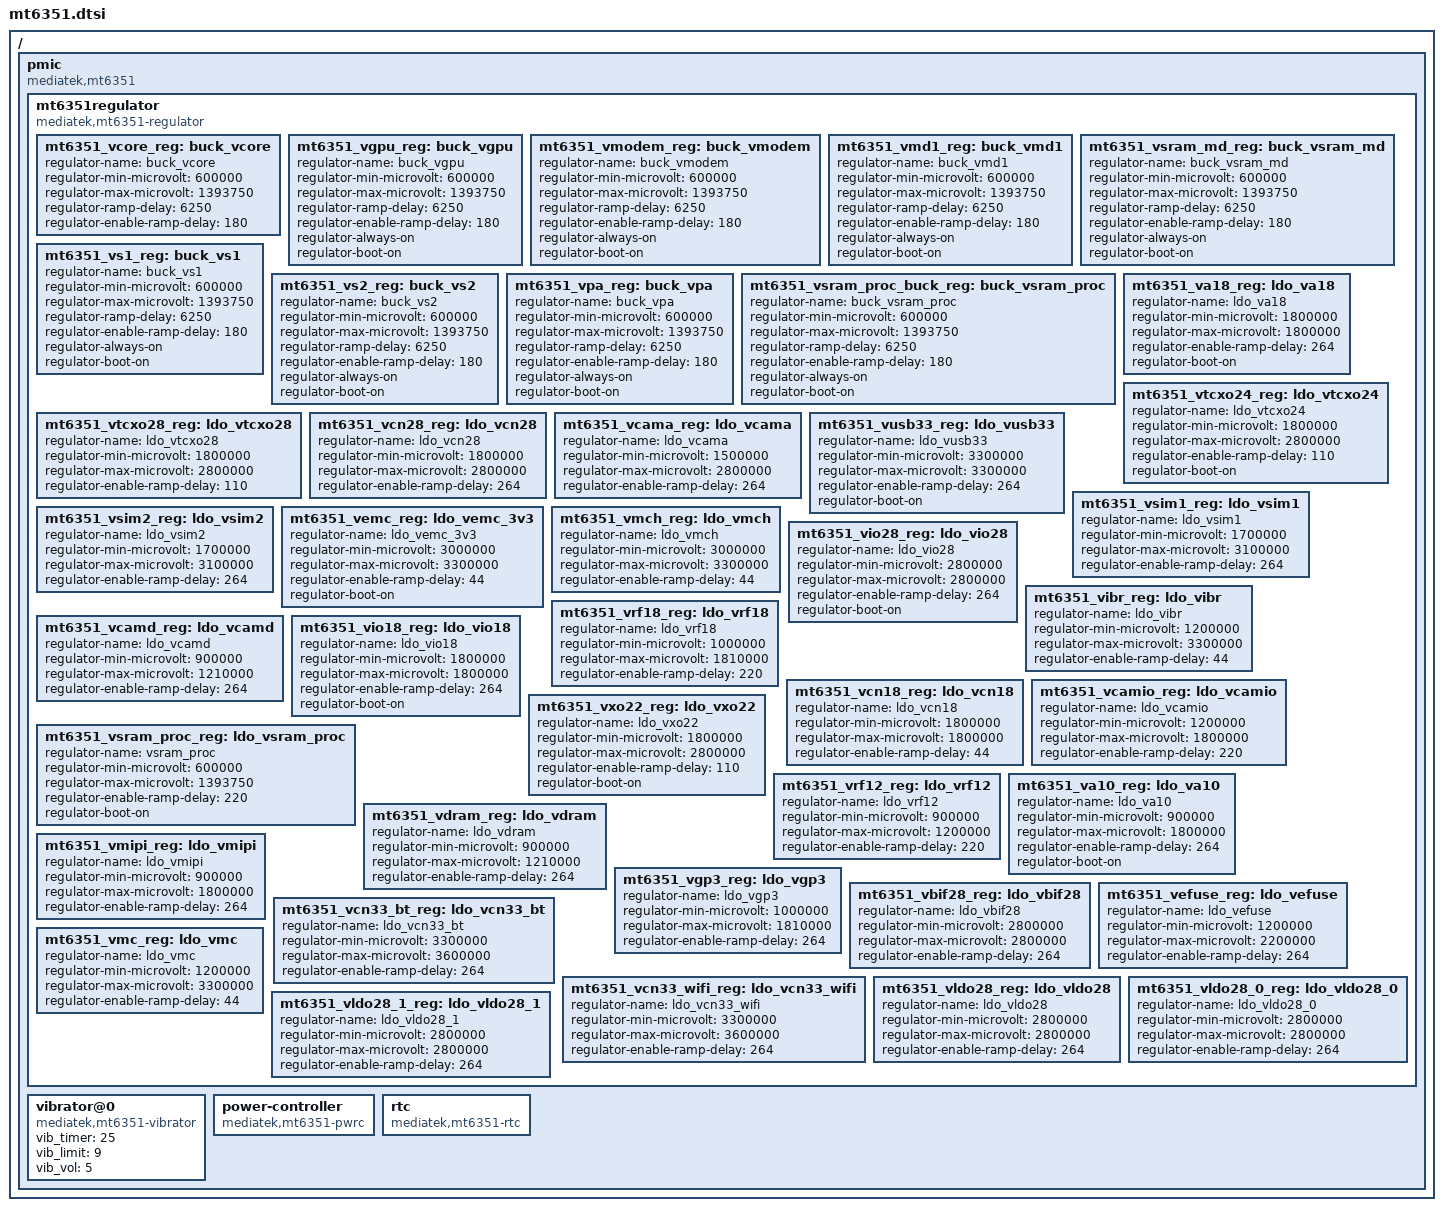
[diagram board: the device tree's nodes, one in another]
// SPDX-License-Identifier: GPL-2.0
/*
 * Mediatek's MT6351 PMIC device tree source
 *
 * Copyright (c) 2013 MediaTek Co., Ltd.
 *              http://www.mediatek.com
 *
 */

/ {
	pmic {
		compatible = "mediatek,mt6351";

		mt6351regulator {
			compatible = "mediatek,mt6351-regulator";

			mt6351_vcore_reg: buck_vcore {
				regulator-name = "buck_vcore";
				regulator-min-microvolt = <600000>;
				regulator-max-microvolt = <1393750>;
				regulator-ramp-delay = <6250>;
				regulator-enable-ramp-delay = <180>;
			};

			mt6351_vgpu_reg: buck_vgpu {
				regulator-name = "buck_vgpu";
				regulator-min-microvolt = <600000>;
				regulator-max-microvolt = <1393750>;
				regulator-ramp-delay = <6250>;
				regulator-enable-ramp-delay = <180>;
				regulator-always-on;
				regulator-boot-on;
			};

			mt6351_vmodem_reg: buck_vmodem {
				regulator-name = "buck_vmodem";
				regulator-min-microvolt = <600000>;
				regulator-max-microvolt = <1393750>;
				regulator-ramp-delay = <6250>;
				regulator-enable-ramp-delay = <180>;
				regulator-always-on;
				regulator-boot-on;
			};

			mt6351_vmd1_reg: buck_vmd1 {
				regulator-name = "buck_vmd1";
				regulator-min-microvolt = <600000>;
				regulator-max-microvolt = <1393750>;
				regulator-ramp-delay = <6250>;
				regulator-enable-ramp-delay = <180>;
				regulator-always-on;
				regulator-boot-on;
			};

			mt6351_vsram_md_reg: buck_vsram_md {
				regulator-name = "buck_vsram_md";
				regulator-min-microvolt = <600000>;
				regulator-max-microvolt = <1393750>;
				regulator-ramp-delay = <6250>;
				regulator-enable-ramp-delay = <180>;
				regulator-always-on;
				regulator-boot-on;
			};

			mt6351_vs1_reg: buck_vs1 {
				regulator-name = "buck_vs1";
				regulator-min-microvolt = <600000>;
				regulator-max-microvolt = <1393750>;
				regulator-ramp-delay = <6250>;
				regulator-enable-ramp-delay = <180>;
				regulator-always-on;
				regulator-boot-on;
			};

			mt6351_vs2_reg: buck_vs2 {
				regulator-name = "buck_vs2";
				regulator-min-microvolt = <600000>;
				regulator-max-microvolt = <1393750>;
				regulator-ramp-delay = <6250>;
				regulator-enable-ramp-delay = <180>;
				regulator-always-on;
				regulator-boot-on;
			};

			mt6351_vpa_reg: buck_vpa {
				regulator-name = "buck_vpa";
				regulator-min-microvolt = <600000>;
				regulator-max-microvolt = <1393750>;
				regulator-ramp-delay = <6250>;
				regulator-enable-ramp-delay = <180>;
				regulator-always-on;
				regulator-boot-on;
			};

			mt6351_vsram_proc_buck_reg: buck_vsram_proc {
				regulator-name = "buck_vsram_proc";
				regulator-min-microvolt = <600000>;
				regulator-max-microvolt = <1393750>;
				regulator-ramp-delay = <6250>;
				regulator-enable-ramp-delay = <180>;
				regulator-always-on;
				regulator-boot-on;
			};

			mt6351_va18_reg: ldo_va18 {
				regulator-name = "ldo_va18";
				regulator-min-microvolt = <1800000>;
				regulator-max-microvolt = <1800000>;
				regulator-enable-ramp-delay = <264>;
				regulator-boot-on;
			};

			mt6351_vtcxo24_reg: ldo_vtcxo24 {
				regulator-name = "ldo_vtcxo24";
				regulator-min-microvolt = <1800000>;
				regulator-max-microvolt = <2800000>;
				regulator-enable-ramp-delay = <110>;
				regulator-boot-on;
			};

			mt6351_vtcxo28_reg: ldo_vtcxo28 {
				regulator-name = "ldo_vtcxo28";
				regulator-min-microvolt = <1800000>;
				regulator-max-microvolt = <2800000>;
				regulator-enable-ramp-delay = <110>;
			};

			mt6351_vcn28_reg: ldo_vcn28 {
				regulator-name = "ldo_vcn28";
				regulator-min-microvolt = <1800000>;
				regulator-max-microvolt = <2800000>;
				regulator-enable-ramp-delay = <264>;
			};

			mt6351_vcama_reg: ldo_vcama {
				regulator-name = "ldo_vcama";
				regulator-min-microvolt = <1500000>;
				regulator-max-microvolt = <2800000>;
				regulator-enable-ramp-delay = <264>;
			};

			mt6351_vusb33_reg: ldo_vusb33 {
				regulator-name = "ldo_vusb33";
				regulator-min-microvolt = <3300000>;
				regulator-max-microvolt = <3300000>;
				regulator-enable-ramp-delay = <264>;
				regulator-boot-on;
			};

			mt6351_vsim1_reg: ldo_vsim1 {
				regulator-name = "ldo_vsim1";
				regulator-min-microvolt = <1700000>;
				regulator-max-microvolt = <3100000>;
				regulator-enable-ramp-delay = <264>;
			};

			mt6351_vsim2_reg: ldo_vsim2 {
				regulator-name = "ldo_vsim2";
				regulator-min-microvolt = <1700000>;
				regulator-max-microvolt = <3100000>;
				regulator-enable-ramp-delay = <264>;
			};

			mt6351_vemc_reg: ldo_vemc_3v3 {
				regulator-name = "ldo_vemc_3v3";
				regulator-min-microvolt = <3000000>;
				regulator-max-microvolt = <3300000>;
				regulator-enable-ramp-delay = <44>;
				regulator-boot-on;
			};

			mt6351_vmch_reg: ldo_vmch {
				regulator-name = "ldo_vmch";
				regulator-min-microvolt = <3000000>;
				regulator-max-microvolt = <3300000>;
				regulator-enable-ramp-delay = <44>;
			};

			mt6351_vio28_reg: ldo_vio28 {
				regulator-name = "ldo_vio28";
				regulator-min-microvolt = <2800000>;
				regulator-max-microvolt = <2800000>;
				regulator-enable-ramp-delay = <264>;
				regulator-boot-on;
			};

			mt6351_vibr_reg: ldo_vibr {
				regulator-name = "ldo_vibr";
				regulator-min-microvolt = <1200000>;
				regulator-max-microvolt = <3300000>;
				regulator-enable-ramp-delay = <44>;
			};

			mt6351_vcamd_reg: ldo_vcamd {
				regulator-name = "ldo_vcamd";
				regulator-min-microvolt = <900000>;
				regulator-max-microvolt = <1210000>;
				regulator-enable-ramp-delay = <264>;
			};

			mt6351_vrf18_reg: ldo_vrf18 {
				regulator-name = "ldo_vrf18";
				regulator-min-microvolt = <1000000>;
				regulator-max-microvolt = <1810000>;
				regulator-enable-ramp-delay = <220>;
			};

			mt6351_vio18_reg: ldo_vio18 {
				regulator-name = "ldo_vio18";
				regulator-min-microvolt = <1800000>;
				regulator-max-microvolt = <1800000>;
				regulator-enable-ramp-delay = <264>;
				regulator-boot-on;
			};

			mt6351_vcn18_reg: ldo_vcn18 {
				regulator-name = "ldo_vcn18";
				regulator-min-microvolt = <1800000>;
				regulator-max-microvolt = <1800000>;
				regulator-enable-ramp-delay = <44>;
			};

			mt6351_vcamio_reg: ldo_vcamio {
				regulator-name = "ldo_vcamio";
				regulator-min-microvolt = <1200000>;
				regulator-max-microvolt = <1800000>;
				regulator-enable-ramp-delay = <220>;
			};

			mt6351_vsram_proc_reg: ldo_vsram_proc {
				regulator-name = "vsram_proc";
				regulator-min-microvolt = <600000>;
				regulator-max-microvolt = <1393750>;
				regulator-enable-ramp-delay = <220>;
				regulator-boot-on;
			};

			mt6351_vxo22_reg: ldo_vxo22 {
				regulator-name = "ldo_vxo22";
				regulator-min-microvolt = <1800000>;
				regulator-max-microvolt = <2800000>;
				regulator-enable-ramp-delay = <110>;
				regulator-boot-on;
			};

			mt6351_vrf12_reg: ldo_vrf12 {
				regulator-name = "ldo_vrf12";
				regulator-min-microvolt = <900000>;
				regulator-max-microvolt = <1200000>;
				regulator-enable-ramp-delay = <220>;
			};

			mt6351_va10_reg: ldo_va10 {
				regulator-name = "ldo_va10";
				regulator-min-microvolt = <900000>;
				regulator-max-microvolt = <1800000>;
				regulator-enable-ramp-delay = <264>;
				regulator-boot-on;
			};

			mt6351_vdram_reg: ldo_vdram {
				regulator-name = "ldo_vdram";
				regulator-min-microvolt = <900000>;
				regulator-max-microvolt = <1210000>;
				regulator-enable-ramp-delay = <264>;
			};

			mt6351_vmipi_reg: ldo_vmipi {
				regulator-name = "ldo_vmipi";
				regulator-min-microvolt = <900000>;
				regulator-max-microvolt = <1800000>;
				regulator-enable-ramp-delay = <264>;
			};

			mt6351_vgp3_reg: ldo_vgp3 {
				regulator-name = "ldo_vgp3";
				regulator-min-microvolt = <1000000>;
				regulator-max-microvolt = <1810000>;
				regulator-enable-ramp-delay = <264>;
			};

			mt6351_vbif28_reg: ldo_vbif28 {
				regulator-name = "ldo_vbif28";
				regulator-min-microvolt = <2800000>;
				regulator-max-microvolt = <2800000>;
				regulator-enable-ramp-delay = <264>;
			};

			mt6351_vefuse_reg: ldo_vefuse {
				regulator-name = "ldo_vefuse";
				regulator-min-microvolt = <1200000>;
				regulator-max-microvolt = <2200000>;
				regulator-enable-ramp-delay = <264>;
			};

			mt6351_vcn33_bt_reg: ldo_vcn33_bt {
				regulator-name = "ldo_vcn33_bt";
				regulator-min-microvolt = <3300000>;
				regulator-max-microvolt = <3600000>;
				regulator-enable-ramp-delay = <264>;
			};

			mt6351_vcn33_wifi_reg: ldo_vcn33_wifi {
				regulator-name = "ldo_vcn33_wifi";
				regulator-min-microvolt = <3300000>;
				regulator-max-microvolt = <3600000>;
				regulator-enable-ramp-delay = <264>;
			};

			mt6351_vldo28_reg: ldo_vldo28 {
				regulator-name = "ldo_vldo28";
				regulator-min-microvolt = <2800000>;
				regulator-max-microvolt = <2800000>;
				regulator-enable-ramp-delay = <264>;
			};

			mt6351_vmc_reg: ldo_vmc {
				regulator-name = "ldo_vmc";
				regulator-min-microvolt = <1200000>;
				regulator-max-microvolt = <3300000>;
				regulator-enable-ramp-delay = <44>;
			};

			mt6351_vldo28_0_reg: ldo_vldo28_0 {
				regulator-name = "ldo_vldo28_0";
				regulator-min-microvolt = <2800000>;
				regulator-max-microvolt = <2800000>;
				regulator-enable-ramp-delay = <264>;
			};

			mt6351_vldo28_1_reg: ldo_vldo28_1 {
				regulator-name = "ldo_vldo28_1";
				regulator-min-microvolt = <2800000>;
				regulator-max-microvolt = <2800000>;
				regulator-enable-ramp-delay = <264>;
			};
		};


		vibrator@0 {
			compatible = "mediatek,mt6351-vibrator";
			vib_timer = <25>;
			vib_limit = <9>;

			// RG_VIBR_VOSEL Output voltage select
			// 0: 1.3V
			// 1: 1.5V
			// 2: 1.8V
			// 3: 2.0V
			// 4: 2.5V
			// 5: 2.8V
			// 6: 3.0V
			// 7: 3.3V
			vib_vol= <5>;
		};

		power-controller {
			compatible = "mediatek,mt6351-pwrc";
		};

		rtc {
			compatible = "mediatek,mt6351-rtc";
		};
	};
};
